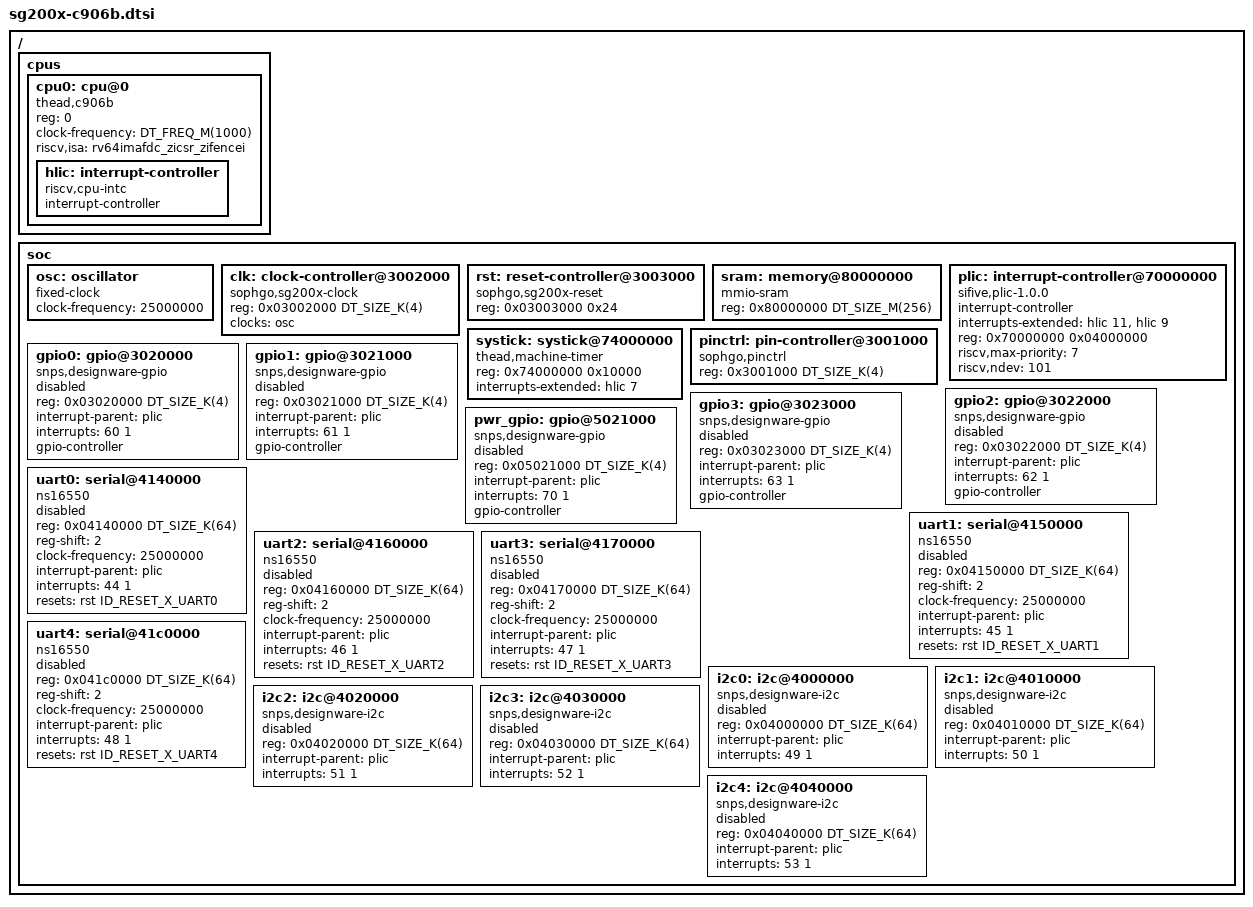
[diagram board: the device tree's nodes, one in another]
#include <freq.h>
#include <mem.h>
#include <zephyr/dt-bindings/i2c/i2c.h>
#include <zephyr/dt-bindings/reset/sophgo_sg200x_reset.h>

/dts-v1/;

/ {
	cpus {
		#address-cells = <1>;
		#size-cells = <0>;
		cpu0: cpu@0 {
			compatible = "thead,c906b";
			reg = <0>;
			clock-frequency = <DT_FREQ_M(1000)>;
			riscv,isa = "rv64imafdc_zicsr_zifencei";

			hlic: interrupt-controller {
				compatible = "riscv,cpu-intc";
				#address-cells = <0>;
				#interrupt-cells = <1>;
				interrupt-controller;
			};
		};
	};

	soc {
		#address-cells = <1>;
		#size-cells = <1>;

		osc: oscillator {
			#clock-cells = <0>;
			compatible = "fixed-clock";
			clock-frequency = <25000000>;
		};

		clk: clock-controller@3002000 {
			compatible = "sophgo,sg200x-clock";
			reg = <0x03002000 DT_SIZE_K(4)>;
			clocks = <&osc>;
			clock-names = "clk";
			#clock-cells = <1>;
		};

		rst: reset-controller@3003000 {
			#reset-cells = <1>;
			compatible = "sophgo,sg200x-reset";
			reg = <0x03003000 0x24>;
			status = "okay";
		};

		sram: memory@80000000 {
			compatible = "mmio-sram";
			reg = <0x80000000 DT_SIZE_M(256)>;
		};

		plic: interrupt-controller@70000000 {
			compatible = "sifive,plic-1.0.0";
			#address-cells = <0>;
			#interrupt-cells = <2>;
			interrupt-controller;
			interrupts-extended = <&hlic 11 &hlic 9>;
			reg = <0x70000000 0x04000000>;
			riscv,max-priority = <7>;
			riscv,ndev = <101>;
		};

		systick: systick@74000000 {
			compatible = "thead,machine-timer";
			reg = <0x74000000 0x10000>;
			interrupts-extended = <&hlic 7>;
		};

		pinctrl: pin-controller@3001000 {
			compatible = "sophgo,pinctrl";
			reg = <0x3001000 DT_SIZE_K(4)>;
		};

		gpio0: gpio@3020000 {
			compatible = "snps,designware-gpio";
			reg = <0x03020000 DT_SIZE_K(4)>;
			interrupt-parent = <&plic>;
			interrupts = <60 1>;
			gpio-controller;
			#gpio-cells = <2>;
			status = "disabled";
		};

		gpio1: gpio@3021000 {
			compatible = "snps,designware-gpio";
			reg = <0x03021000 DT_SIZE_K(4)>;
			interrupt-parent = <&plic>;
			interrupts = <61 1>;
			gpio-controller;
			#gpio-cells = <2>;
			status = "disabled";
		};

		gpio2: gpio@3022000 {
			compatible = "snps,designware-gpio";
			reg = <0x03022000 DT_SIZE_K(4)>;
			interrupt-parent = <&plic>;
			interrupts = <62 1>;
			gpio-controller;
			#gpio-cells = <2>;
			status = "disabled";
		};

		gpio3: gpio@3023000 {
			compatible = "snps,designware-gpio";
			reg = <0x03023000 DT_SIZE_K(4)>;
			interrupt-parent = <&plic>;
			interrupts = <63 1>;
			gpio-controller;
			#gpio-cells = <2>;
			status = "disabled";
		};

		pwr_gpio: gpio@5021000 {
			compatible = "snps,designware-gpio";
			reg = <0x05021000 DT_SIZE_K(4)>;
			interrupt-parent = <&plic>;
			interrupts = <70 1>;
			gpio-controller;
			#gpio-cells = <2>;
			status = "disabled";
		};

		uart0:  serial@4140000 {
			compatible = "ns16550";
			reg = <0x04140000 DT_SIZE_K(64)>;
			reg-shift = <2>;
			clock-frequency = <25000000>;
			interrupt-parent = <&plic>;
			interrupts = <44 1>;
			interrupt-names = "uart0";
			resets = <&rst ID_RESET_X_UART0>;
			status = "disabled";
		};

		uart1:  serial@4150000 {
			compatible = "ns16550";
			reg = <0x04150000 DT_SIZE_K(64)>;
			reg-shift = <2>;
			clock-frequency = <25000000>;
			interrupt-parent = <&plic>;
			interrupts = <45 1>;
			interrupt-names = "uart1";
			resets = <&rst ID_RESET_X_UART1>;
			status = "disabled";
		};

		uart2:  serial@4160000 {
			compatible = "ns16550";
			reg = <0x04160000 DT_SIZE_K(64)>;
			reg-shift = <2>;
			clock-frequency = <25000000>;
			interrupt-parent = <&plic>;
			interrupts = <46 1>;
			interrupt-names = "uart2";
			resets = <&rst ID_RESET_X_UART2>;
			status = "disabled";
		};
	
		uart3:  serial@4170000 {
			compatible = "ns16550";
			reg = <0x04170000 DT_SIZE_K(64)>;
			reg-shift = <2>;
			clock-frequency = <25000000>;
			interrupt-parent = <&plic>;
			interrupts = <47 1>;
			interrupt-names = "uart3";
			resets = <&rst ID_RESET_X_UART3>;
			status = "disabled";
		};

		uart4:  serial@41c0000 {
			compatible = "ns16550";
			reg = <0x041c0000 DT_SIZE_K(64)>;
			reg-shift = <2>;
			clock-frequency = <25000000>;
			interrupt-parent = <&plic>;
			interrupts = <48 1>;
			interrupt-names = "uart4";
			resets = <&rst ID_RESET_X_UART4>;
			status = "disabled";
		};

		i2c0: i2c@4000000 {
			compatible = "snps,designware-i2c";
			reg = <0x04000000 DT_SIZE_K(64)>;
			interrupt-parent = <&plic>;
			interrupts = <49 1>;
			interrupt-names = "i2c0";
		//	resets = <&rst ID_RESET_X_I2C0>;
			status = "disabled";
		};

		i2c1: i2c@4010000 {
			compatible = "snps,designware-i2c";
			reg = <0x04010000 DT_SIZE_K(64)>;
			interrupt-parent = <&plic>;
			interrupts = <50 1>;
			interrupt-names = "i2c1";
		//	resets = <&rst ID_RESET_X_I2C1>;
			status = "disabled";
		};

		i2c2: i2c@4020000 {
			compatible = "snps,designware-i2c";
			reg = <0x04020000 DT_SIZE_K(64)>;
			interrupt-parent = <&plic>;
			interrupts = <51 1>;
			interrupt-names = "i2c2";
		//	resets = <&rst ID_RESET_X_I2C2>;
			status = "disabled";
		};

		i2c3: i2c@4030000 {
			compatible = "snps,designware-i2c";
			reg = <0x04030000 DT_SIZE_K(64)>;
			interrupt-parent = <&plic>;
			interrupts = <52 1>;
			interrupt-names = "i2c3";
		//	resets = <&rst ID_RESET_X_I2C3>;
			status = "disabled";
		};

		i2c4: i2c@4040000 {
			compatible = "snps,designware-i2c";
                        #address-cells = <1>;
                        #size-cells = <0>;
			reg = <0x04040000 DT_SIZE_K(64)>;
			interrupt-parent = <&plic>;
			interrupts = <53 1>;
			interrupt-names = "i2c4";
		//	resets = <&rst ID_RESET_X_I2C4>;
			status = "disabled";
		};
	};
};

